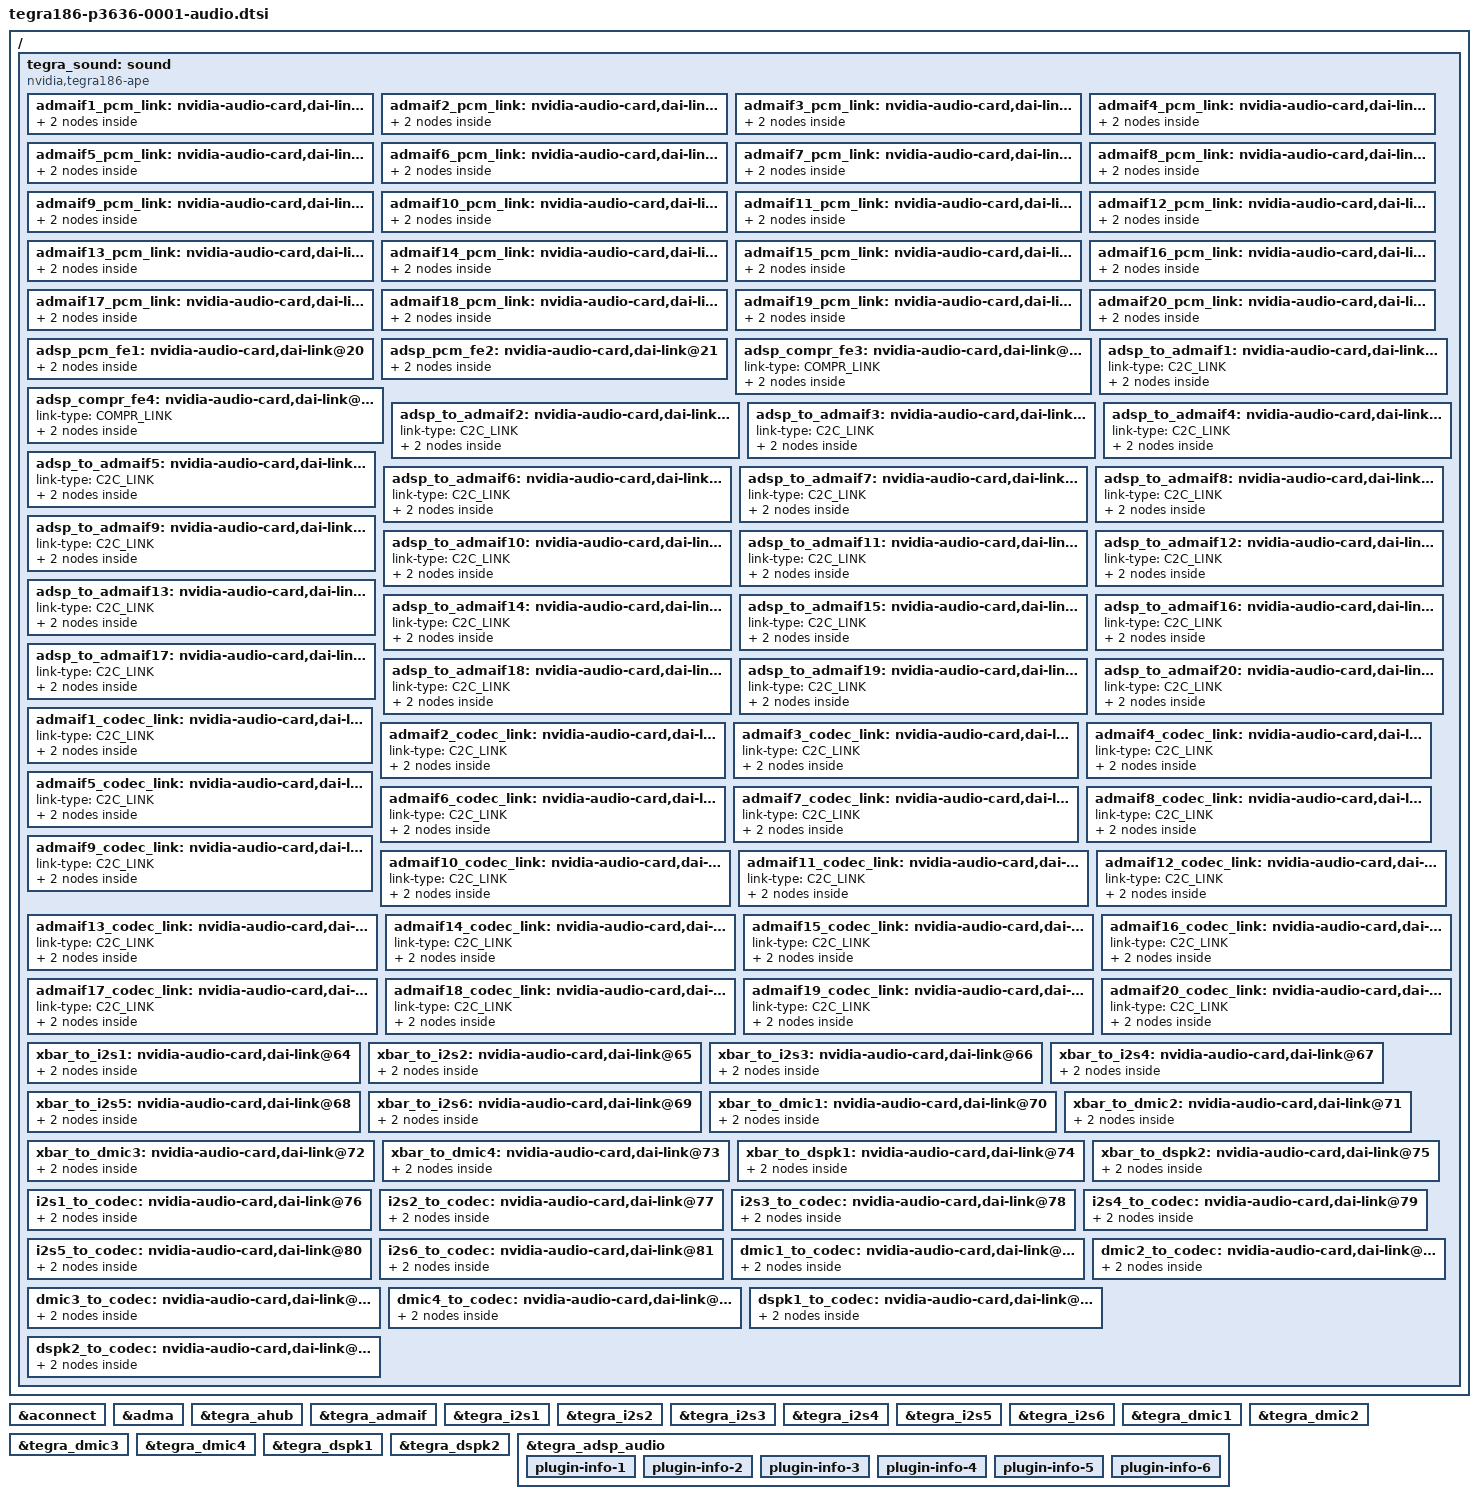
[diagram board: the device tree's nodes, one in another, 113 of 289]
// SPDX-License-Identifier: GPL-2.0
/*
 * Tegra186 P3636/P3509 ALSA machine-card wiring for the 5.10 port.
 *
 * This deliberately wires only the T186 audio IP blocks present in
 * arch/arm64/boot/dts/nvidia/tegra186.dtsi: ADMAIF, ADSP, XBAR,
 * I2S, DMIC and DSPK.  The later T194/T234 accelerator links in
 * tegra186-audio-dai-links.dtsi are not instantiated here.
 */

#include <dt-bindings/sound/tegra-asoc-dais.h>

#define ADMAIF_FIFO(i) (TEGRA186_ADMAIF_FIFO_OFFSET + i - 1)
#define ADMAIF_CIF(i)  (TEGRA186_ADMAIF_CIF_OFFSET + i - 1)

/ {
	tegra_sound: sound {
		compatible = "nvidia,tegra186-ape";
		nvidia-audio-card,name = "NVIDIA Jetson TX2 NX APE";

		clocks = <&bpmp TEGRA186_CLK_PLLA>,
			 <&bpmp TEGRA186_CLK_PLL_A_OUT0>,
			 <&bpmp TEGRA186_CLK_AUD_MCLK>;
		clock-names = "pll_a", "pll_a_out0", "extern1";
		assigned-clocks = <&bpmp TEGRA186_CLK_AUD_MCLK>;
		assigned-clock-parents = <&bpmp TEGRA186_CLK_PLL_A_OUT0>;
		nvidia-audio-card,mclk-fs = <256>;

		iommus = <&smmu TEGRA186_SID_APE>;
		iommu-resv-regions =
			<0x0 0x00000000 0x0 0x40000000
			 0x0 0x60000000 0xffffffff 0xffffffff>;

		status = "okay";
		/* ADMAIF <--> XBAR PCM links */
		admaif1_pcm_link: nvidia-audio-card,dai-link@0 {
			status = "okay";

			cpu {
				sound-dai = <&tegra_admaif ADMAIF1>;
			};
			codec {
				sound-dai = <&tegra_axbar XBAR_ADMAIF1>;
			};
		};

		admaif2_pcm_link: nvidia-audio-card,dai-link@1 {
			status = "okay";

			cpu {
				sound-dai = <&tegra_admaif ADMAIF2>;
			};
			codec {
				sound-dai = <&tegra_axbar XBAR_ADMAIF2>;
			};
		};

		admaif3_pcm_link: nvidia-audio-card,dai-link@2 {
			status = "okay";

			cpu {
				sound-dai = <&tegra_admaif ADMAIF3>;
			};
			codec {
				sound-dai = <&tegra_axbar XBAR_ADMAIF3>;
			};
		};

		admaif4_pcm_link: nvidia-audio-card,dai-link@3 {
			status = "okay";

			cpu {
				sound-dai = <&tegra_admaif ADMAIF4>;
			};
			codec {
				sound-dai = <&tegra_axbar XBAR_ADMAIF4>;
			};
		};

		admaif5_pcm_link: nvidia-audio-card,dai-link@4 {
			status = "okay";

			cpu {
				sound-dai = <&tegra_admaif ADMAIF5>;
			};
			codec {
				sound-dai = <&tegra_axbar XBAR_ADMAIF5>;
			};
		};

		admaif6_pcm_link: nvidia-audio-card,dai-link@5 {
			status = "okay";

			cpu {
				sound-dai = <&tegra_admaif ADMAIF6>;
			};
			codec {
				sound-dai = <&tegra_axbar XBAR_ADMAIF6>;
			};
		};

		admaif7_pcm_link: nvidia-audio-card,dai-link@6 {
			status = "okay";

			cpu {
				sound-dai = <&tegra_admaif ADMAIF7>;
			};
			codec {
				sound-dai = <&tegra_axbar XBAR_ADMAIF7>;
			};
		};

		admaif8_pcm_link: nvidia-audio-card,dai-link@7 {
			status = "okay";

			cpu {
				sound-dai = <&tegra_admaif ADMAIF8>;
			};
			codec {
				sound-dai = <&tegra_axbar XBAR_ADMAIF8>;
			};
		};

		admaif9_pcm_link: nvidia-audio-card,dai-link@8 {
			status = "okay";

			cpu {
				sound-dai = <&tegra_admaif ADMAIF9>;
			};
			codec {
				sound-dai = <&tegra_axbar XBAR_ADMAIF9>;
			};
		};

		admaif10_pcm_link: nvidia-audio-card,dai-link@9 {
			status = "okay";

			cpu {
				sound-dai = <&tegra_admaif ADMAIF10>;
			};
			codec {
				sound-dai = <&tegra_axbar XBAR_ADMAIF10>;
			};
		};

		admaif11_pcm_link: nvidia-audio-card,dai-link@10 {
			status = "okay";

			cpu {
				sound-dai = <&tegra_admaif ADMAIF11>;
			};
			codec {
				sound-dai = <&tegra_axbar XBAR_ADMAIF11>;
			};
		};

		admaif12_pcm_link: nvidia-audio-card,dai-link@11 {
			status = "okay";

			cpu {
				sound-dai = <&tegra_admaif ADMAIF12>;
			};
			codec {
				sound-dai = <&tegra_axbar XBAR_ADMAIF12>;
			};
		};

		admaif13_pcm_link: nvidia-audio-card,dai-link@12 {
			status = "okay";

			cpu {
				sound-dai = <&tegra_admaif ADMAIF13>;
			};
			codec {
				sound-dai = <&tegra_axbar XBAR_ADMAIF13>;
			};
		};

		admaif14_pcm_link: nvidia-audio-card,dai-link@13 {
			status = "okay";

			cpu {
				sound-dai = <&tegra_admaif ADMAIF14>;
			};
			codec {
				sound-dai = <&tegra_axbar XBAR_ADMAIF14>;
			};
		};

		admaif15_pcm_link: nvidia-audio-card,dai-link@14 {
			status = "okay";

			cpu {
				sound-dai = <&tegra_admaif ADMAIF15>;
			};
			codec {
				sound-dai = <&tegra_axbar XBAR_ADMAIF15>;
			};
		};

		admaif16_pcm_link: nvidia-audio-card,dai-link@15 {
			status = "okay";

			cpu {
				sound-dai = <&tegra_admaif ADMAIF16>;
			};
			codec {
				sound-dai = <&tegra_axbar XBAR_ADMAIF16>;
			};
		};

		admaif17_pcm_link: nvidia-audio-card,dai-link@16 {
			status = "okay";

			cpu {
				sound-dai = <&tegra_admaif ADMAIF17>;
			};
			codec {
				sound-dai = <&tegra_axbar XBAR_ADMAIF17>;
			};
		};

		admaif18_pcm_link: nvidia-audio-card,dai-link@17 {
			status = "okay";

			cpu {
				sound-dai = <&tegra_admaif ADMAIF18>;
			};
			codec {
				sound-dai = <&tegra_axbar XBAR_ADMAIF18>;
			};
		};

		admaif19_pcm_link: nvidia-audio-card,dai-link@18 {
			status = "okay";

			cpu {
				sound-dai = <&tegra_admaif ADMAIF19>;
			};
			codec {
				sound-dai = <&tegra_axbar XBAR_ADMAIF19>;
			};
		};

		admaif20_pcm_link: nvidia-audio-card,dai-link@19 {
			status = "okay";

			cpu {
				sound-dai = <&tegra_admaif ADMAIF20>;
			};
			codec {
				sound-dai = <&tegra_axbar XBAR_ADMAIF20>;
			};
		};

		/*
		 * List ADSP PCM/COMPR links just after ADMAIF PCM links.
		 * This keeps the ADSP PCM/COMPR device IDs continuous from
		 * ADMAIF PCM devices and remain the same even if links
		 * which follow these are removed or any new links are added.
		 */
		adsp_pcm_fe1: nvidia-audio-card,dai-link@20 {
			status = "okay";

			cpu {
				sound-dai = <&tegra_adsp_audio ADSP_PCM1>;
			};
			codec {
				sound-dai = <&tegra_adsp_audio ADSP_FE1>;
			};
		};

		adsp_pcm_fe2: nvidia-audio-card,dai-link@21 {
			status = "okay";

			cpu {
				sound-dai = <&tegra_adsp_audio ADSP_PCM2>;
			};
			codec {
				sound-dai = <&tegra_adsp_audio ADSP_FE2>;
			};
		};

		adsp_compr_fe3: nvidia-audio-card,dai-link@22 {
			status = "okay";

			link-type = <COMPR_LINK>;
			cpu {
				sound-dai = <&tegra_adsp_audio ADSP_COMPR1>;
			};
			codec {
				sound-dai = <&tegra_adsp_audio ADSP_FE3>;
			};
		};

		adsp_compr_fe4: nvidia-audio-card,dai-link@23 {
			status = "okay";

			link-type = <COMPR_LINK>;
			cpu {
				sound-dai = <&tegra_adsp_audio ADSP_COMPR2>;
			};
			codec {
				sound-dai = <&tegra_adsp_audio ADSP_FE4>;
			};
		};

		/* ADSP to ADMAIF links */
		adsp_to_admaif1: nvidia-audio-card,dai-link@24 {
			status = "okay";

			link-type = <C2C_LINK>;
			cpu {
				sound-dai = <&tegra_adsp_audio ADSP_ADMAIF1>;
			};
			codec {
				sound-dai = <&tegra_admaif ADMAIF_FIFO(1)>;
			};
		};

		adsp_to_admaif2: nvidia-audio-card,dai-link@25 {
			status = "okay";

			link-type = <C2C_LINK>;
			cpu {
				sound-dai = <&tegra_adsp_audio ADSP_ADMAIF2>;
			};
			codec {
				sound-dai = <&tegra_admaif ADMAIF_FIFO(2)>;
			};
		};

		adsp_to_admaif3: nvidia-audio-card,dai-link@26 {
			status = "okay";

			link-type = <C2C_LINK>;
			cpu {
				sound-dai = <&tegra_adsp_audio ADSP_ADMAIF3>;
			};
			codec {
				sound-dai = <&tegra_admaif ADMAIF_FIFO(3)>;
			};
		};

		adsp_to_admaif4: nvidia-audio-card,dai-link@27 {
			status = "okay";

			link-type = <C2C_LINK>;
			cpu {
				sound-dai = <&tegra_adsp_audio ADSP_ADMAIF4>;
			};
			codec {
				sound-dai = <&tegra_admaif ADMAIF_FIFO(4)>;
			};
		};

		adsp_to_admaif5: nvidia-audio-card,dai-link@28 {
			status = "okay";

			link-type = <C2C_LINK>;
			cpu {
				sound-dai = <&tegra_adsp_audio ADSP_ADMAIF5>;
			};
			codec {
				sound-dai = <&tegra_admaif ADMAIF_FIFO(5)>;
			};
		};

		adsp_to_admaif6: nvidia-audio-card,dai-link@29 {
			status = "okay";

			link-type = <C2C_LINK>;
			cpu {
				sound-dai = <&tegra_adsp_audio ADSP_ADMAIF6>;
			};
			codec {
				sound-dai = <&tegra_admaif ADMAIF_FIFO(6)>;
			};
		};

		adsp_to_admaif7: nvidia-audio-card,dai-link@30 {
			status = "okay";

			link-type = <C2C_LINK>;
			cpu {
				sound-dai = <&tegra_adsp_audio ADSP_ADMAIF7>;
			};
			codec {
				sound-dai = <&tegra_admaif ADMAIF_FIFO(7)>;
			};
		};

		adsp_to_admaif8: nvidia-audio-card,dai-link@31 {
			status = "okay";

			link-type = <C2C_LINK>;
			cpu {
				sound-dai = <&tegra_adsp_audio ADSP_ADMAIF8>;
			};
			codec {
				sound-dai = <&tegra_admaif ADMAIF_FIFO(8)>;
			};
		};

		adsp_to_admaif9: nvidia-audio-card,dai-link@32 {
			status = "okay";

			link-type = <C2C_LINK>;
			cpu {
				sound-dai = <&tegra_adsp_audio ADSP_ADMAIF9>;
			};
			codec {
				sound-dai = <&tegra_admaif ADMAIF_FIFO(9)>;
			};
		};

		adsp_to_admaif10: nvidia-audio-card,dai-link@33 {
			status = "okay";

			link-type = <C2C_LINK>;
			cpu {
				sound-dai = <&tegra_adsp_audio ADSP_ADMAIF10>;
			};
			codec {
				sound-dai = <&tegra_admaif ADMAIF_FIFO(10)>;
			};
		};

		adsp_to_admaif11: nvidia-audio-card,dai-link@34 {
			status = "okay";

			link-type = <C2C_LINK>;
			cpu {
				sound-dai = <&tegra_adsp_audio ADSP_ADMAIF11>;
			};
			codec {
				sound-dai = <&tegra_admaif ADMAIF_FIFO(11)>;
			};
		};

		adsp_to_admaif12: nvidia-audio-card,dai-link@35 {
			status = "okay";

			link-type = <C2C_LINK>;
			cpu {
				sound-dai = <&tegra_adsp_audio ADSP_ADMAIF12>;
			};
			codec {
				sound-dai = <&tegra_admaif ADMAIF_FIFO(12)>;
			};
		};

		adsp_to_admaif13: nvidia-audio-card,dai-link@36 {
			status = "okay";

			link-type = <C2C_LINK>;
			cpu {
				sound-dai = <&tegra_adsp_audio ADSP_ADMAIF13>;
			};
			codec {
				sound-dai = <&tegra_admaif ADMAIF_FIFO(13)>;
			};
		};

		adsp_to_admaif14: nvidia-audio-card,dai-link@37 {
			status = "okay";

			link-type = <C2C_LINK>;
			cpu {
				sound-dai = <&tegra_adsp_audio ADSP_ADMAIF14>;
			};
			codec {
				sound-dai = <&tegra_admaif ADMAIF_FIFO(14)>;
			};
		};

		adsp_to_admaif15: nvidia-audio-card,dai-link@38 {
			status = "okay";

			link-type = <C2C_LINK>;
			cpu {
				sound-dai = <&tegra_adsp_audio ADSP_ADMAIF15>;
			};
			codec {
				sound-dai = <&tegra_admaif ADMAIF_FIFO(15)>;
			};
		};

		adsp_to_admaif16: nvidia-audio-card,dai-link@39 {
			status = "okay";

			link-type = <C2C_LINK>;
			cpu {
				sound-dai = <&tegra_adsp_audio ADSP_ADMAIF16>;
			};
			codec {
				sound-dai = <&tegra_admaif ADMAIF_FIFO(16)>;
			};
		};

		adsp_to_admaif17: nvidia-audio-card,dai-link@40 {
			status = "okay";

			link-type = <C2C_LINK>;
			cpu {
				sound-dai = <&tegra_adsp_audio ADSP_ADMAIF17>;
			};
			codec {
				sound-dai = <&tegra_admaif ADMAIF_FIFO(17)>;
			};
		};

		adsp_to_admaif18: nvidia-audio-card,dai-link@41 {
			status = "okay";

			link-type = <C2C_LINK>;
			cpu {
				sound-dai = <&tegra_adsp_audio ADSP_ADMAIF18>;
			};
			codec {
				sound-dai = <&tegra_admaif ADMAIF_FIFO(18)>;
			};
		};

		adsp_to_admaif19: nvidia-audio-card,dai-link@42 {
			status = "okay";

			link-type = <C2C_LINK>;
			cpu {
				sound-dai = <&tegra_adsp_audio ADSP_ADMAIF19>;
			};
			codec {
				sound-dai = <&tegra_admaif ADMAIF_FIFO(19)>;
			};
		};

		adsp_to_admaif20: nvidia-audio-card,dai-link@43 {
			status = "okay";

			link-type = <C2C_LINK>;
			cpu {
				sound-dai = <&tegra_adsp_audio ADSP_ADMAIF20>;
			};
			codec {
				sound-dai = <&tegra_admaif ADMAIF_FIFO(20)>;
			};
		};

		/* ADMAIF <--> XBAR CODEC links */
		admaif1_codec_link: nvidia-audio-card,dai-link@44 {
			status = "okay";

			link-type = <C2C_LINK>;
			cpu {
				sound-dai = <&tegra_admaif ADMAIF_CIF(1)>;
			};
			codec {
				sound-dai = <&tegra_axbar XBAR_ADMAIF1>;
			};
		};

		admaif2_codec_link: nvidia-audio-card,dai-link@45 {
			status = "okay";

			link-type = <C2C_LINK>;
			cpu {
				sound-dai = <&tegra_admaif ADMAIF_CIF(2)>;
			};
			codec {
				sound-dai = <&tegra_axbar XBAR_ADMAIF2>;
			};
		};

		admaif3_codec_link: nvidia-audio-card,dai-link@46 {
			status = "okay";

			link-type = <C2C_LINK>;
			cpu {
				sound-dai = <&tegra_admaif ADMAIF_CIF(3)>;
			};
			codec {
				sound-dai = <&tegra_axbar XBAR_ADMAIF3>;
			};
		};

		admaif4_codec_link: nvidia-audio-card,dai-link@47 {
			status = "okay";

			link-type = <C2C_LINK>;
			cpu {
				sound-dai = <&tegra_admaif ADMAIF_CIF(4)>;
			};
			codec {
				sound-dai = <&tegra_axbar XBAR_ADMAIF4>;
			};
		};

		admaif5_codec_link: nvidia-audio-card,dai-link@48 {
			status = "okay";

			link-type = <C2C_LINK>;
			cpu {
				sound-dai = <&tegra_admaif ADMAIF_CIF(5)>;
			};
			codec {
				sound-dai = <&tegra_axbar XBAR_ADMAIF5>;
			};
		};

		admaif6_codec_link: nvidia-audio-card,dai-link@49 {
			status = "okay";

			link-type = <C2C_LINK>;
			cpu {
				sound-dai = <&tegra_admaif ADMAIF_CIF(6)>;
			};
			codec {
				sound-dai = <&tegra_axbar XBAR_ADMAIF6>;
			};
		};

		admaif7_codec_link: nvidia-audio-card,dai-link@50 {
			status = "okay";

			link-type = <C2C_LINK>;
			cpu {
				sound-dai = <&tegra_admaif ADMAIF_CIF(7)>;
			};
			codec {
				sound-dai = <&tegra_axbar XBAR_ADMAIF7>;
			};
		};

		admaif8_codec_link: nvidia-audio-card,dai-link@51 {
			status = "okay";

			link-type = <C2C_LINK>;
			cpu {
				sound-dai = <&tegra_admaif ADMAIF_CIF(8)>;
			};
			codec {
				sound-dai = <&tegra_axbar XBAR_ADMAIF8>;
			};
		};

		admaif9_codec_link: nvidia-audio-card,dai-link@52 {
			status = "okay";

			link-type = <C2C_LINK>;
			cpu {
				sound-dai = <&tegra_admaif ADMAIF_CIF(9)>;
			};
			codec {
				sound-dai = <&tegra_axbar XBAR_ADMAIF9>;
			};
		};

		admaif10_codec_link: nvidia-audio-card,dai-link@53 {
			status = "okay";

			link-type = <C2C_LINK>;
			cpu {
				sound-dai = <&tegra_admaif ADMAIF_CIF(10)>;
			};
			codec {
				sound-dai = <&tegra_axbar XBAR_ADMAIF10>;
			};
		};

		admaif11_codec_link: nvidia-audio-card,dai-link@54 {
			status = "okay";

			link-type = <C2C_LINK>;
			cpu {
				sound-dai = <&tegra_admaif ADMAIF_CIF(11)>;
			};
			codec {
				sound-dai = <&tegra_axbar XBAR_ADMAIF11>;
			};
		};

		admaif12_codec_link: nvidia-audio-card,dai-link@55 {
			status = "okay";

			link-type = <C2C_LINK>;
			cpu {
				sound-dai = <&tegra_admaif ADMAIF_CIF(12)>;
			};
			codec {
				sound-dai = <&tegra_axbar XBAR_ADMAIF12>;
			};
		};

		admaif13_codec_link: nvidia-audio-card,dai-link@56 {
			status = "okay";

			link-type = <C2C_LINK>;
			cpu {
				sound-dai = <&tegra_admaif ADMAIF_CIF(13)>;
			};
			codec {
				sound-dai = <&tegra_axbar XBAR_ADMAIF13>;
			};
		};

		admaif14_codec_link: nvidia-audio-card,dai-link@57 {
			status = "okay";

			link-type = <C2C_LINK>;
			cpu {
				sound-dai = <&tegra_admaif ADMAIF_CIF(14)>;
			};
			codec {
				sound-dai = <&tegra_axbar XBAR_ADMAIF14>;
			};
		};

		admaif15_codec_link: nvidia-audio-card,dai-link@58 {
			status = "okay";

			link-type = <C2C_LINK>;
			cpu {
				sound-dai = <&tegra_admaif ADMAIF_CIF(15)>;
			};
			codec {
				sound-dai = <&tegra_axbar XBAR_ADMAIF15>;
			};
		};

		admaif16_codec_link: nvidia-audio-card,dai-link@59 {
			status = "okay";

			link-type = <C2C_LINK>;
			cpu {
				sound-dai = <&tegra_admaif ADMAIF_CIF(16)>;
			};
			codec {
				sound-dai = <&tegra_axbar XBAR_ADMAIF16>;
			};
		};

		admaif17_codec_link: nvidia-audio-card,dai-link@60 {
			status = "okay";

			link-type = <C2C_LINK>;
			cpu {
				sound-dai = <&tegra_admaif ADMAIF_CIF(17)>;
			};
			codec {
				sound-dai = <&tegra_axbar XBAR_ADMAIF17>;
			};
		};

		admaif18_codec_link: nvidia-audio-card,dai-link@61 {
			status = "okay";

			link-type = <C2C_LINK>;
			cpu {
				sound-dai = <&tegra_admaif ADMAIF_CIF(18)>;
			};
			codec {
				sound-dai = <&tegra_axbar XBAR_ADMAIF18>;
			};
		};

		admaif19_codec_link: nvidia-audio-card,dai-link@62 {
			status = "okay";

			link-type = <C2C_LINK>;
			cpu {
				sound-dai = <&tegra_admaif ADMAIF_CIF(19)>;
			};
			codec {
				sound-dai = <&tegra_axbar XBAR_ADMAIF19>;
			};
		};

		admaif20_codec_link: nvidia-audio-card,dai-link@63 {
			status = "okay";

			link-type = <C2C_LINK>;
			cpu {
				sound-dai = <&tegra_admaif ADMAIF_CIF(20)>;
			};
			codec {
				sound-dai = <&tegra_axbar XBAR_ADMAIF20>;
			};
		};

		/* XBAR <---> I2S links */
		xbar_to_i2s1: nvidia-audio-card,dai-link@64 {
			status = "okay";

			format = "i2s";
			link-type = <C2C_LINK>;
			cpu {
				sound-dai = <&tegra_axbar XBAR_I2S1>;
			};
			codec {
				sound-dai = <&tegra_i2s1 I2S_CIF>;
				prefix = "I2S1";
			};
		};

		xbar_to_i2s2: nvidia-audio-card,dai-link@65 {
			status = "okay";

			format = "i2s";
			link-type = <C2C_LINK>;
			cpu {
				sound-dai = <&tegra_axbar XBAR_I2S2>;
			};
			codec {
				sound-dai = <&tegra_i2s2 I2S_CIF>;
				prefix = "I2S2";
			};
		};

		xbar_to_i2s3: nvidia-audio-card,dai-link@66 {
			status = "okay";

			format = "i2s";
			link-type = <C2C_LINK>;
			cpu {
				sound-dai = <&tegra_axbar XBAR_I2S3>;
			};
			codec {
				sound-dai = <&tegra_i2s3 I2S_CIF>;
				prefix = "I2S3";
			};
		};

		xbar_to_i2s4: nvidia-audio-card,dai-link@67 {
			status = "okay";

			format = "i2s";
			link-type = <C2C_LINK>;
			cpu {
				sound-dai = <&tegra_axbar XBAR_I2S4>;
			};
			codec {
				sound-dai = <&tegra_i2s4 I2S_CIF>;
				prefix = "I2S4";
			};
		};

		xbar_to_i2s5: nvidia-audio-card,dai-link@68 {
			status = "okay";

			format = "i2s";
			link-type = <C2C_LINK>;
			cpu {
				sound-dai = <&tegra_axbar XBAR_I2S5>;
			};
			codec {
				sound-dai = <&tegra_i2s5 I2S_CIF>;
				prefix = "I2S5";
			};
		};

		xbar_to_i2s6: nvidia-audio-card,dai-link@69 {
			status = "okay";

			format = "i2s";
			link-type = <C2C_LINK>;
			cpu {
				sound-dai = <&tegra_axbar XBAR_I2S6>;
			};
			codec {
				sound-dai = <&tegra_i2s6 I2S_CIF>;
				prefix = "I2S6";
			};
		};

		/* XBAR <----> DMIC links */
		xbar_to_dmic1: nvidia-audio-card,dai-link@70 {
			status = "okay";

			format = "i2s";
			link-type = <C2C_LINK>;
			cpu {
				sound-dai = <&tegra_axbar XBAR_DMIC1>;
			};
			codec {
				sound-dai = <&tegra_dmic1 DMIC_CIF>;
				prefix = "DMIC1";
			};
		};

		xbar_to_dmic2: nvidia-audio-card,dai-link@71 {
			status = "okay";

			format = "i2s";
			link-type = <C2C_LINK>;
			cpu {
				sound-dai = <&tegra_axbar XBAR_DMIC2>;
			};
			codec {
				sound-dai = <&tegra_dmic2 DMIC_CIF>;
				prefix = "DMIC2";
			};
		};

		xbar_to_dmic3: nvidia-audio-card,dai-link@72 {
			status = "okay";

			format = "i2s";
			link-type = <C2C_LINK>;
			cpu {
				sound-dai = <&tegra_axbar XBAR_DMIC3>;
			};
			codec {
				sound-dai = <&tegra_dmic3 DMIC_CIF>;
				prefix = "DMIC3";
			};
		};

		xbar_to_dmic4: nvidia-audio-card,dai-link@73 {
			status = "okay";

			format = "i2s";
			link-type = <C2C_LINK>;
			cpu {
				sound-dai = <&tegra_axbar XBAR_DMIC4>;
			};
			codec {
				sound-dai = <&tegra_dmic4 DMIC_CIF>;
				prefix = "DMIC4";
			};
		};

		/* XBAR <----> DSPK links */
		xbar_to_dspk1: nvidia-audio-card,dai-link@74 {
			status = "okay";

			format = "i2s";
			link-type = <C2C_LINK>;
			cpu {
				sound-dai = <&tegra_axbar XBAR_DSPK1>;
			};
			codec {
				sound-dai = <&tegra_dspk1 DSPK_CIF>;
				prefix = "DSPK1";
			};
		};

		xbar_to_dspk2: nvidia-audio-card,dai-link@75 {
			status = "okay";

			format = "i2s";
			link-type = <C2C_LINK>;
			cpu {
				sound-dai = <&tegra_axbar XBAR_DSPK2>;
			};
			codec {
				sound-dai = <&tegra_dspk2 DSPK_CIF>;
				prefix = "DSPK2";
			};
		};

		/* I2S(DAP) <----> I2S(Dummy) links */
		i2s1_to_codec: nvidia-audio-card,dai-link@76 {
			status = "okay";

			format = "i2s";
			link-type = <C2C_LINK>;
			i2s1_cpu: cpu {
				sound-dai = <&tegra_i2s1 I2S_DAP>;
			};
			codec {
				sound-dai = <&tegra_i2s1 I2S_DUMMY>;
			};
		};

		i2s2_to_codec: nvidia-audio-card,dai-link@77 {
			status = "okay";

			format = "i2s";
			link-type = <C2C_LINK>;
			i2s2_cpu: cpu {
				sound-dai = <&tegra_i2s2 I2S_DAP>;
			};
			codec {
				sound-dai = <&tegra_i2s2 I2S_DUMMY>;
			};
		};

		i2s3_to_codec: nvidia-audio-card,dai-link@78 {
			status = "okay";

			format = "i2s";
			link-type = <C2C_LINK>;
			i2s3_cpu: cpu {
				sound-dai = <&tegra_i2s3 I2S_DAP>;
			};
			codec {
				sound-dai = <&tegra_i2s3 I2S_DUMMY>;
			};
		};

		i2s4_to_codec: nvidia-audio-card,dai-link@79 {
			status = "okay";

			format = "i2s";
			link-type = <C2C_LINK>;
			i2s4_cpu: cpu {
				sound-dai = <&tegra_i2s4 I2S_DAP>;
			};
			codec {
				sound-dai = <&tegra_i2s4 I2S_DUMMY>;
			};
		};

		i2s5_to_codec: nvidia-audio-card,dai-link@80 {
			status = "okay";

			format = "i2s";
			link-type = <C2C_LINK>;
			i2s5_cpu: cpu {
				sound-dai = <&tegra_i2s5 I2S_DAP>;
			};
			codec {
				sound-dai = <&tegra_i2s5 I2S_DUMMY>;
			};
		};

		i2s6_to_codec: nvidia-audio-card,dai-link@81 {
			status = "okay";

			format = "i2s";
			link-type = <C2C_LINK>;
			i2s6_cpu: cpu {
				sound-dai = <&tegra_i2s6 I2S_DAP>;
			};
			codec {
				sound-dai = <&tegra_i2s6 I2S_DUMMY>;
			};
		};

		/* DMIC(DAP) <----> DMIC(Dummy) links */
		dmic1_to_codec: nvidia-audio-card,dai-link@82 {
			status = "okay";

			format = "i2s";
			link-type = <C2C_LINK>;
			cpu {
				sound-dai = <&tegra_dmic1 DMIC_DAP>;
			};
			codec {
				sound-dai = <&tegra_dmic1 DMIC_DUMMY>;
			};
		};

		dmic2_to_codec: nvidia-audio-card,dai-link@83 {
			status = "okay";

			format = "i2s";
			link-type = <C2C_LINK>;
			cpu {
				sound-dai = <&tegra_dmic2 DMIC_DAP>;
			};
			codec {
				sound-dai = <&tegra_dmic2 DMIC_DUMMY>;
			};
		};

		dmic3_to_codec: nvidia-audio-card,dai-link@84 {
			status = "okay";

			format = "i2s";
			link-type = <C2C_LINK>;
			cpu {
				sound-dai = <&tegra_dmic3 DMIC_DAP>;
			};
			codec {
				sound-dai = <&tegra_dmic3 DMIC_DUMMY>;
			};
		};

		dmic4_to_codec: nvidia-audio-card,dai-link@85 {
			status = "okay";

			format = "i2s";
			link-type = <C2C_LINK>;
			cpu {
				sound-dai = <&tegra_dmic4 DMIC_DAP>;
			};
			codec {
				sound-dai = <&tegra_dmic4 DMIC_DUMMY>;
			};
		};

		/* DSPK(DAP) <----> DSPK(Dummy) links */
		dspk1_to_codec: nvidia-audio-card,dai-link@86 {
			status = "okay";

			format = "i2s";
			link-type = <C2C_LINK>;
			cpu {
				sound-dai = <&tegra_dspk1 DSPK_DAP>;
			};
			codec {
				sound-dai = <&tegra_dspk1 DSPK_DUMMY>;
			};
		};

		dspk2_to_codec: nvidia-audio-card,dai-link@87 {
			status = "okay";

			format = "i2s";
			link-type = <C2C_LINK>;
			cpu {
				sound-dai = <&tegra_dspk2 DSPK_DAP>;
			};
			codec {
				sound-dai = <&tegra_dspk2 DSPK_DUMMY>;
			};
		};
	};
};

/* Enable the audio fabric required by the machine card above. */
&aconnect {
	status = "okay";
};

&adma {
	status = "okay";
};

&tegra_ahub {
	status = "okay";
};

&tegra_admaif {
	status = "okay";
};

&tegra_i2s1 { status = "okay"; };
&tegra_i2s2 { status = "okay"; };
&tegra_i2s3 { status = "okay"; };
&tegra_i2s4 { status = "okay"; };
&tegra_i2s5 { status = "okay"; };
&tegra_i2s6 { status = "okay"; };

&tegra_dmic1 { status = "okay"; };
&tegra_dmic2 { status = "okay"; };
&tegra_dmic3 { status = "okay"; };
&tegra_dmic4 { status = "okay"; };

&tegra_dspk1 { status = "okay"; };
&tegra_dspk2 { status = "okay"; };

&tegra_adsp_audio {
	status = "okay";
	compr-ops = <1>;
	num-plugin = <6>;

	plugin-info-1 {
		plugin-name = "mp3-dec1";
		firmware-name = "nvmp3dec.elf";
		widget-name = "MP3-DEC1";
	};
	plugin-info-2 {
		plugin-name = "spkprot";
		firmware-name = "nvspkprot.elf";
		widget-name = "SPKPROT-SW";
	};
	plugin-info-3 {
		plugin-name = "src";
		firmware-name = "nvsrc.elf";
		widget-name = "SRC";
	};
	plugin-info-4 {
		plugin-name = "aac-dec1";
		firmware-name = "nvaacdec.elf";
		widget-name = "AAC-DEC1";
	};
	plugin-info-5 {
		plugin-name = "aec";
		firmware-name = "nvoice.elf";
		widget-name = "AEC";
	};
	plugin-info-6 {
		plugin-name = "wire";
		firmware-name = "libnvwirefx.elf";
		widget-name = "WIRE";
	};
};
